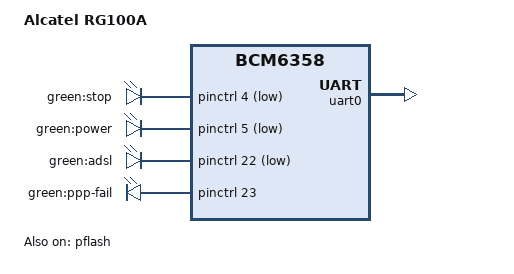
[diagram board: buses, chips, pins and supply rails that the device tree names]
#include "bcm6358.dtsi"

#include <dt-bindings/input/input.h>

/ {
	model = "Alcatel RG100A";
	compatible = "alcatel,rg100a", "brcm,bcm6358";

	chosen {
		bootargs = "rootfstype=squashfs,jffs2 noinitrd console=ttyS0,115200";
		stdout-path = "serial0:115200n8";
	};

	leds {
		compatible = "gpio-leds";

		stop_green {
			label = "green:stop";
			gpios = <&pinctrl 4 1>;
		};
		power_green {
			label = "green:power";
			gpios = <&pinctrl 5 1>;
			default-state = "on";
		};
		adsl_green {
			label = "green:adsl";
			gpios = <&pinctrl 22 1>;
		};
		ppp_fail_green {
			label = "green:ppp-fail";
			gpios = <&pinctrl 23 0>;
		};
	};
};

&pflash {
	status = "okay";

	partitions {
		compatible = "fixed-partitions";
		#address-cells = <1>;
		#size-cells = <1>;

		cfe@0 {
			label = "CFE";
			reg = <0x000000 0x020000>;
			read-only;
		};

		linux@20000 {
			label = "linux";
			reg = <0x020000 0xfc0000>;
			compatible = "brcm,bcm963xx-imagetag";
		};

		nvram@fe0000 {
			label = "nvram";
			reg = <0xfe0000 0x020000>;
		};
	};
};

&uart0 {
	status = "okay";
};
